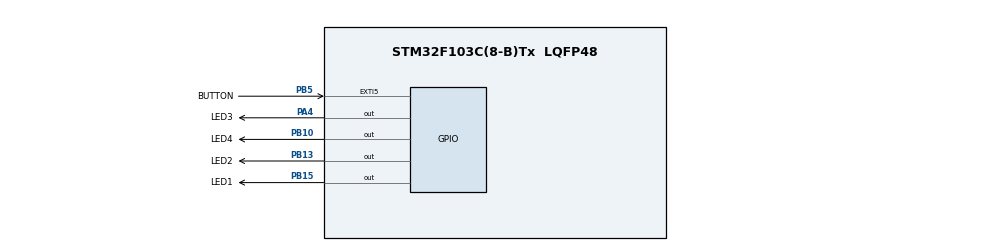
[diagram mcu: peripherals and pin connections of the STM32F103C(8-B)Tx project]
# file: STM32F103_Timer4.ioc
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Mcu.Family=STM32F1
Mcu.Name=STM32F103C(8-B)Tx
Mcu.Package=LQFP48
NVIC.EXTI9_5_IRQn=true\:0\:0\:false\:false\:true\:true\:true\:true
NVIC.PriorityGroup=NVIC_PRIORITYGROUP_4
NVIC.TIM1_UP_IRQn=true\:1\:0\:true\:false\:true\:true\:true\:true
NVIC.TIM2_IRQn=true\:1\:0\:true\:false\:true\:true\:true\:true
NVIC.TIM3_IRQn=true\:1\:0\:true\:false\:true\:true\:true\:true
NVIC.TIM4_IRQn=true\:1\:0\:true\:false\:true\:true\:true\:true
PA13.Mode=Serial_Wire
PA13.Signal=SYS_JTMS-SWDIO
PA14.Mode=Serial_Wire
PA14.Signal=SYS_JTCK-SWCLK
PA4.GPIO_Label=LED3
PA4.Signal=GPIO_Output
PB10.GPIO_Label=LED4
PB10.Signal=GPIO_Output
PB13.GPIO_Label=LED2
PB13.Signal=GPIO_Output
PB15.GPIO_Label=LED1
PB15.Signal=GPIO_Output
PB5.GPIO_Label=BUTTON
PB5.GPIO_ModeDefaultEXTI=GPIO_MODE_IT_FALLING
PB5.GPIO_PuPd=GPIO_PULLUP
PB5.Signal=GPXTI5
ProjectManager.HeapSize=0x200
ProjectManager.StackSize=0x400
ProjectManager.TargetToolchain=STM32CubeIDE
RCC.APB1Freq_Value=8000000
RCC.APB2Freq_Value=8000000
TIM1.Period=1000-1
TIM1.Prescaler=8000-1
TIM2.Period=1000-1
TIM2.Prescaler=8000-1
TIM3.Period=1000-1
TIM3.Prescaler=8000-1
TIM4.Period=1000-1
TIM4.Prescaler=8000-1
VP_TIM1_VS_ClockSourceINT.Mode=Internal
VP_TIM2_VS_ClockSourceINT.Mode=Internal
VP_TIM3_VS_ClockSourceINT.Mode=Internal
VP_TIM4_VS_ClockSourceINT.Mode=Internal
board=custom

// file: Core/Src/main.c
/* USER CODE BEGIN Header */
/**
  ******************************************************************************
  * @file           : main.c
  * @brief          : Main program body
  ******************************************************************************
  * @attention
  *
  * Copyright (c) 2023 STMicroelectronics.
  * All rights reserved.
  *
  * This software is licensed under terms that can be found in the LICENSE file
  * in the root directory of this software component.
  * If no LICENSE file comes with this software, it is provided AS-IS.
  *
  ******************************************************************************
  */
/* USER CODE END Header */
#include "main.h"

TIM_HandleTypeDef htim1;
TIM_HandleTypeDef htim2;
TIM_HandleTypeDef htim3;
TIM_HandleTypeDef htim4;

void SystemClock_Config(void);
static void MX_GPIO_Init(void);
static void MX_TIM1_Init(void);
static void MX_TIM2_Init(void);
static void MX_TIM3_Init(void);
static void MX_TIM4_Init(void);

/* USER CODE BEGIN 0 */
extern uint8_t debounceflag;
/* USER CODE END 0 */

int main(void)
{

  /* MCU Configuration--------------------------------------------------------*/

  /* Reset of all peripherals, Initializes the Flash interface and the Systick. */
  HAL_Init();

  /* Configure the system clock */
  SystemClock_Config();

  /* Initialize all configured peripherals */
  MX_GPIO_Init();
  MX_TIM1_Init();
  MX_TIM2_Init();
  MX_TIM3_Init();
  MX_TIM4_Init();
  /* USER CODE BEGIN 2 */
  HAL_TIM_Base_Start_IT(&htim1);
  HAL_TIM_Base_Start_IT(&htim2);
  HAL_TIM_Base_Start_IT(&htim3);
  HAL_TIM_Base_Start_IT(&htim4);
  /* USER CODE END 2 */

  /* Infinite loop */
  /* USER CODE BEGIN WHILE */
  while (1)
  {

	  if(debounceflag==1)
	  	 	  {

	  	 		  HAL_Delay(200);
	  	 		  debounceflag=0;
	  	 	  }
	  	 	  HAL_Delay(10);

    /* USER CODE END WHILE */

  }
}

void SystemClock_Config(void)
{
  RCC_OscInitTypeDef RCC_OscInitStruct = {0};
  RCC_ClkInitTypeDef RCC_ClkInitStruct = {0};

  /** Initializes the RCC Oscillators according to the specified parameters
  * in the RCC_OscInitTypeDef structure.
  */
  RCC_OscInitStruct.OscillatorType = RCC_OSCILLATORTYPE_HSI;
  RCC_OscInitStruct.HSIState = RCC_HSI_ON;
  RCC_OscInitStruct.HSICalibrationValue = RCC_HSICALIBRATION_DEFAULT;
  RCC_OscInitStruct.PLL.PLLState = RCC_PLL_NONE;
  if (HAL_RCC_OscConfig(&RCC_OscInitStruct) != HAL_OK)
  {
    Error_Handler();
  }

  /** Initializes the CPU, AHB and APB buses clocks
  */
  RCC_ClkInitStruct.ClockType = RCC_CLOCKTYPE_HCLK|RCC_CLOCKTYPE_SYSCLK
                              |RCC_CLOCKTYPE_PCLK1|RCC_CLOCKTYPE_PCLK2;
  RCC_ClkInitStruct.SYSCLKSource = RCC_SYSCLKSOURCE_HSI;
  RCC_ClkInitStruct.AHBCLKDivider = RCC_SYSCLK_DIV1;
  RCC_ClkInitStruct.APB1CLKDivider = RCC_HCLK_DIV1;
  RCC_ClkInitStruct.APB2CLKDivider = RCC_HCLK_DIV1;

  if (HAL_RCC_ClockConfig(&RCC_ClkInitStruct, FLASH_LATENCY_0) != HAL_OK)
  {
    Error_Handler();
  }
}

static void MX_TIM1_Init(void)
{

  TIM_ClockConfigTypeDef sClockSourceConfig = {0};
  TIM_MasterConfigTypeDef sMasterConfig = {0};

  htim1.Instance = TIM1;
  htim1.Init.Prescaler = 8000-1;
  htim1.Init.CounterMode = TIM_COUNTERMODE_UP;
  htim1.Init.Period = 1000-1;
  htim1.Init.ClockDivision = TIM_CLOCKDIVISION_DIV1;
  htim1.Init.RepetitionCounter = 0;
  htim1.Init.AutoReloadPreload = TIM_AUTORELOAD_PRELOAD_DISABLE;
  if (HAL_TIM_Base_Init(&htim1) != HAL_OK)
  {
    Error_Handler();
  }
  sClockSourceConfig.ClockSource = TIM_CLOCKSOURCE_INTERNAL;
  if (HAL_TIM_ConfigClockSource(&htim1, &sClockSourceConfig) != HAL_OK)
  {
    Error_Handler();
  }
  sMasterConfig.MasterOutputTrigger = TIM_TRGO_RESET;
  sMasterConfig.MasterSlaveMode = TIM_MASTERSLAVEMODE_DISABLE;
  if (HAL_TIMEx_MasterConfigSynchronization(&htim1, &sMasterConfig) != HAL_OK)
  {
    Error_Handler();
  }

}

static void MX_TIM2_Init(void)
{

  TIM_ClockConfigTypeDef sClockSourceConfig = {0};
  TIM_MasterConfigTypeDef sMasterConfig = {0};

  htim2.Instance = TIM2;
  htim2.Init.Prescaler = 8000-1;
  htim2.Init.CounterMode = TIM_COUNTERMODE_UP;
  htim2.Init.Period = 1000-1;
  htim2.Init.ClockDivision = TIM_CLOCKDIVISION_DIV1;
  htim2.Init.AutoReloadPreload = TIM_AUTORELOAD_PRELOAD_DISABLE;
  if (HAL_TIM_Base_Init(&htim2) != HAL_OK)
  {
    Error_Handler();
  }
  sClockSourceConfig.ClockSource = TIM_CLOCKSOURCE_INTERNAL;
  if (HAL_TIM_ConfigClockSource(&htim2, &sClockSourceConfig) != HAL_OK)
  {
    Error_Handler();
  }
  sMasterConfig.MasterOutputTrigger = TIM_TRGO_RESET;
  sMasterConfig.MasterSlaveMode = TIM_MASTERSLAVEMODE_DISABLE;
  if (HAL_TIMEx_MasterConfigSynchronization(&htim2, &sMasterConfig) != HAL_OK)
  {
    Error_Handler();
  }

}

static void MX_TIM3_Init(void)
{

  TIM_ClockConfigTypeDef sClockSourceConfig = {0};
  TIM_MasterConfigTypeDef sMasterConfig = {0};

  htim3.Instance = TIM3;
  htim3.Init.Prescaler = 8000-1;
  htim3.Init.CounterMode = TIM_COUNTERMODE_UP;
  htim3.Init.Period = 1000-1;
  htim3.Init.ClockDivision = TIM_CLOCKDIVISION_DIV1;
  htim3.Init.AutoReloadPreload = TIM_AUTORELOAD_PRELOAD_DISABLE;
  if (HAL_TIM_Base_Init(&htim3) != HAL_OK)
  {
    Error_Handler();
  }
  sClockSourceConfig.ClockSource = TIM_CLOCKSOURCE_INTERNAL;
  if (HAL_TIM_ConfigClockSource(&htim3, &sClockSourceConfig) != HAL_OK)
  {
    Error_Handler();
  }
  sMasterConfig.MasterOutputTrigger = TIM_TRGO_RESET;
  sMasterConfig.MasterSlaveMode = TIM_MASTERSLAVEMODE_DISABLE;
  if (HAL_TIMEx_MasterConfigSynchronization(&htim3, &sMasterConfig) != HAL_OK)
  {
    Error_Handler();
  }

}

static void MX_TIM4_Init(void)
{

  TIM_ClockConfigTypeDef sClockSourceConfig = {0};
  TIM_MasterConfigTypeDef sMasterConfig = {0};

  htim4.Instance = TIM4;
  htim4.Init.Prescaler = 8000-1;
  htim4.Init.CounterMode = TIM_COUNTERMODE_UP;
  htim4.Init.Period = 1000-1;
  htim4.Init.ClockDivision = TIM_CLOCKDIVISION_DIV1;
  htim4.Init.AutoReloadPreload = TIM_AUTORELOAD_PRELOAD_DISABLE;
  if (HAL_TIM_Base_Init(&htim4) != HAL_OK)
  {
    Error_Handler();
  }
  sClockSourceConfig.ClockSource = TIM_CLOCKSOURCE_INTERNAL;
  if (HAL_TIM_ConfigClockSource(&htim4, &sClockSourceConfig) != HAL_OK)
  {
    Error_Handler();
  }
  sMasterConfig.MasterOutputTrigger = TIM_TRGO_RESET;
  sMasterConfig.MasterSlaveMode = TIM_MASTERSLAVEMODE_DISABLE;
  if (HAL_TIMEx_MasterConfigSynchronization(&htim4, &sMasterConfig) != HAL_OK)
  {
    Error_Handler();
  }

}

static void MX_GPIO_Init(void)
{
  GPIO_InitTypeDef GPIO_InitStruct = {0};

  /* GPIO Ports Clock Enable */
  __HAL_RCC_GPIOA_CLK_ENABLE();
  __HAL_RCC_GPIOB_CLK_ENABLE();

  /*Configure GPIO pin Output Level */
  HAL_GPIO_WritePin(LED3_GPIO_Port, LED3_Pin, GPIO_PIN_RESET);

  /*Configure GPIO pin Output Level */
  HAL_GPIO_WritePin(GPIOB, LED4_Pin|LED2_Pin|LED1_Pin, GPIO_PIN_RESET);

  /*Configure GPIO pin : LED3_Pin */
  GPIO_InitStruct.Pin = LED3_Pin;
  GPIO_InitStruct.Mode = GPIO_MODE_OUTPUT_PP;
  GPIO_InitStruct.Pull = GPIO_NOPULL;
  GPIO_InitStruct.Speed = GPIO_SPEED_FREQ_LOW;
  HAL_GPIO_Init(LED3_GPIO_Port, &GPIO_InitStruct);

  /*Configure GPIO pins : LED4_Pin LED2_Pin LED1_Pin */
  GPIO_InitStruct.Pin = LED4_Pin|LED2_Pin|LED1_Pin;
  GPIO_InitStruct.Mode = GPIO_MODE_OUTPUT_PP;
  GPIO_InitStruct.Pull = GPIO_NOPULL;
  GPIO_InitStruct.Speed = GPIO_SPEED_FREQ_LOW;
  HAL_GPIO_Init(GPIOB, &GPIO_InitStruct);

  /*Configure GPIO pin : BUTTON_Pin */
  GPIO_InitStruct.Pin = BUTTON_Pin;
  GPIO_InitStruct.Mode = GPIO_MODE_IT_FALLING;
  GPIO_InitStruct.Pull = GPIO_PULLUP;
  HAL_GPIO_Init(BUTTON_GPIO_Port, &GPIO_InitStruct);

  /* EXTI interrupt init*/
  HAL_NVIC_SetPriority(EXTI9_5_IRQn, 0, 0);
  HAL_NVIC_EnableIRQ(EXTI9_5_IRQn);

}

void Error_Handler(void)
{
  __disable_irq();
  while (1)
  {
  }
}
